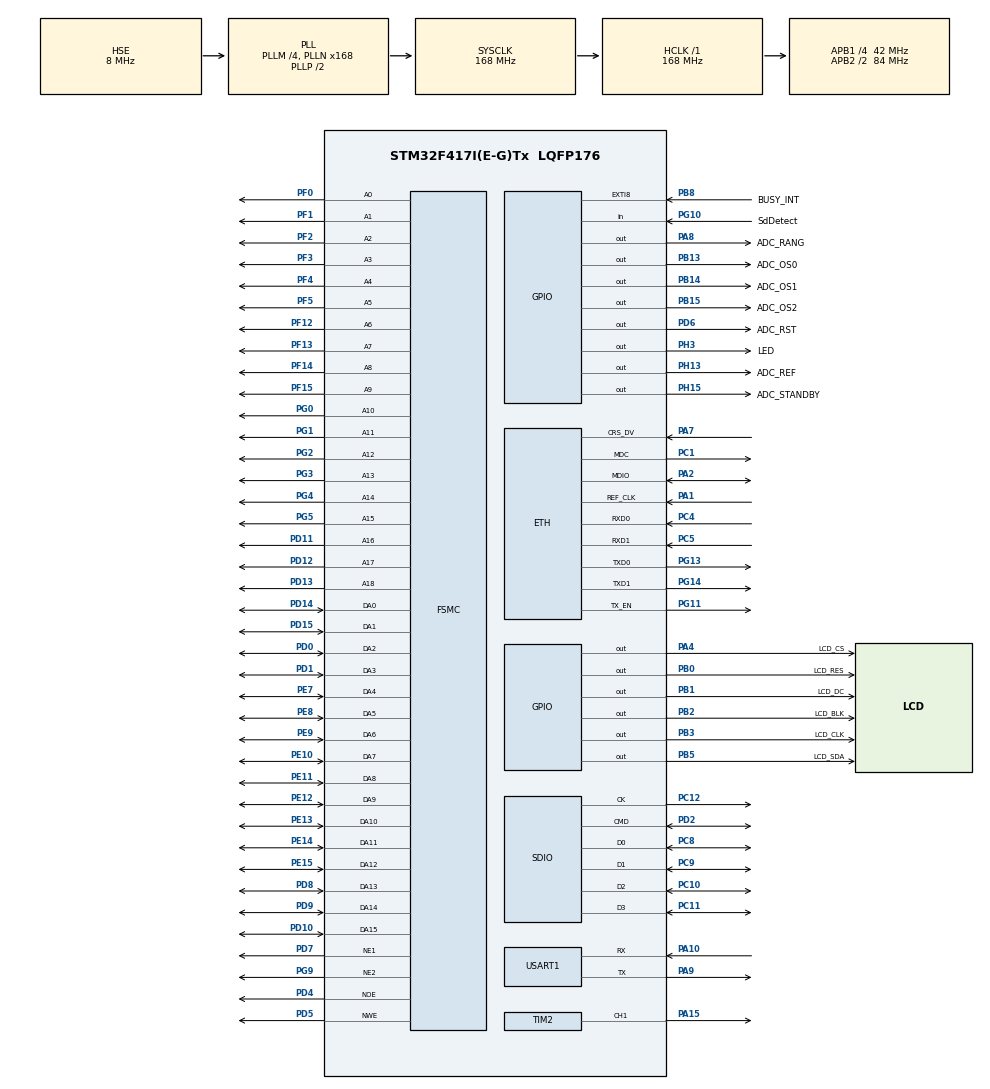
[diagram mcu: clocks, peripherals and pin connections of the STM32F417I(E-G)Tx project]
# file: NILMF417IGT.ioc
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Dma.MEMTOMEM.0.Direction=DMA_MEMORY_TO_MEMORY
Dma.MEMTOMEM.0.FIFOMode=DMA_FIFOMODE_ENABLE
Dma.MEMTOMEM.0.FIFOThreshold=DMA_FIFO_THRESHOLD_FULL
Dma.MEMTOMEM.0.Instance=DMA2_Stream0
Dma.MEMTOMEM.0.MemBurst=DMA_MBURST_SINGLE
Dma.MEMTOMEM.0.MemDataAlignment=DMA_MDATAALIGN_HALFWORD
Dma.MEMTOMEM.0.MemInc=DMA_MINC_ENABLE
Dma.MEMTOMEM.0.Mode=DMA_NORMAL
Dma.MEMTOMEM.0.PeriphBurst=DMA_PBURST_SINGLE
Dma.MEMTOMEM.0.PeriphDataAlignment=DMA_PDATAALIGN_HALFWORD
Dma.MEMTOMEM.0.PeriphInc=DMA_PINC_DISABLE
Dma.MEMTOMEM.0.Priority=DMA_PRIORITY_VERY_HIGH
Dma.Request0=MEMTOMEM
Dma.Request1=USART1_TX
Dma.Request2=SDIO_RX
Dma.Request3=SDIO_TX
Dma.SDIO_RX.2.Direction=DMA_PERIPH_TO_MEMORY
Dma.SDIO_RX.2.FIFOMode=DMA_FIFOMODE_ENABLE
Dma.SDIO_RX.2.FIFOThreshold=DMA_FIFO_THRESHOLD_FULL
Dma.SDIO_RX.2.Instance=DMA2_Stream3
Dma.SDIO_RX.2.MemBurst=DMA_MBURST_INC4
Dma.SDIO_RX.2.MemDataAlignment=DMA_MDATAALIGN_WORD
Dma.SDIO_RX.2.MemInc=DMA_MINC_ENABLE
Dma.SDIO_RX.2.Mode=DMA_PFCTRL
Dma.SDIO_RX.2.PeriphBurst=DMA_PBURST_INC4
Dma.SDIO_RX.2.PeriphDataAlignment=DMA_PDATAALIGN_WORD
Dma.SDIO_RX.2.PeriphInc=DMA_PINC_DISABLE
Dma.SDIO_RX.2.Priority=DMA_PRIORITY_VERY_HIGH
Dma.SDIO_TX.3.Direction=DMA_MEMORY_TO_PERIPH
Dma.SDIO_TX.3.FIFOMode=DMA_FIFOMODE_ENABLE
Dma.SDIO_TX.3.FIFOThreshold=DMA_FIFO_THRESHOLD_FULL
Dma.SDIO_TX.3.Instance=DMA2_Stream6
Dma.SDIO_TX.3.MemBurst=DMA_MBURST_INC4
Dma.SDIO_TX.3.MemDataAlignment=DMA_MDATAALIGN_WORD
Dma.SDIO_TX.3.MemInc=DMA_MINC_ENABLE
Dma.SDIO_TX.3.Mode=DMA_PFCTRL
Dma.SDIO_TX.3.PeriphBurst=DMA_PBURST_INC4
Dma.SDIO_TX.3.PeriphDataAlignment=DMA_PDATAALIGN_WORD
Dma.SDIO_TX.3.PeriphInc=DMA_PINC_DISABLE
Dma.SDIO_TX.3.Priority=DMA_PRIORITY_VERY_HIGH
Dma.USART1_TX.1.Direction=DMA_MEMORY_TO_PERIPH
Dma.USART1_TX.1.FIFOMode=DMA_FIFOMODE_ENABLE
Dma.USART1_TX.1.FIFOThreshold=DMA_FIFO_THRESHOLD_FULL
Dma.USART1_TX.1.Instance=DMA2_Stream7
Dma.USART1_TX.1.MemBurst=DMA_MBURST_SINGLE
Dma.USART1_TX.1.MemDataAlignment=DMA_MDATAALIGN_BYTE
Dma.USART1_TX.1.MemInc=DMA_MINC_ENABLE
Dma.USART1_TX.1.Mode=DMA_NORMAL
Dma.USART1_TX.1.PeriphBurst=DMA_PBURST_SINGLE
Dma.USART1_TX.1.PeriphDataAlignment=DMA_PDATAALIGN_BYTE
Dma.USART1_TX.1.PeriphInc=DMA_PINC_DISABLE
Dma.USART1_TX.1.Priority=DMA_PRIORITY_VERY_HIGH
ETH.MediaInterface=ETH_MEDIA_INTERFACE_RMII
ETH.PHY_DUPLEX_STATUS=0x0010
ETH.PHY_Name_RMII=userPHY
ETH.PHY_SPEED_STATUS=0x0004
ETH.PHY_SR=0x1F
ETH.PHY_User_Name=LAN8720A
ETH.PhyAddress=0
FSMC.AddressSetupTime2=15
FSMC.BusTurnAroundDuration2=15
FSMC.DataSetupTime2=255
FSMC.ExtendedMode2=FSMC_EXTENDED_MODE_DISABLE
FSMC.WriteOperation1=FSMC_WRITE_OPERATION_ENABLE
FSMC.WriteOperation2=FSMC_WRITE_OPERATION_ENABLE
LWIP.GATEWAY_ADDRESS=192.168.008.001
LWIP.IP_ADDRESS=192.168.008.156
LWIP.LWIP_DHCP=0
LWIP.MEMP_NUM_PBUF=50
LWIP.MEMP_NUM_TCP_SEG=128
LWIP.MEM_SIZE=30720
LWIP.NETMASK_ADDRESS=255.255.255.000
LWIP.PBUF_POOL_BUFSIZE=2067
LWIP.PBUF_POOL_SIZE=16
LWIP.TCP_MSS=1460
LWIP.TCP_SND_BUF=93440
LWIP.TCP_SND_QUEUELEN=128
LWIP.TCP_WND=5840
LWIP.Version=v2.1.2_Cube
Mcu.Family=STM32F4
Mcu.Name=STM32F417I(E-G)Tx
Mcu.Package=LQFP176
NVIC.DMA2_Stream0_IRQn=true\:0\:0\:false\:false\:true\:true\:true\:true
NVIC.DMA2_Stream3_IRQn=true\:0\:0\:false\:false\:true\:false\:true\:true
NVIC.DMA2_Stream6_IRQn=true\:0\:0\:false\:false\:true\:false\:true\:true
NVIC.DMA2_Stream7_IRQn=true\:0\:0\:false\:false\:true\:false\:true\:true
NVIC.ETH_IRQn=true\:0\:0\:false\:false\:true\:true\:true\:true
NVIC.EXTI9_5_IRQn=true\:0\:0\:true\:false\:true\:true\:true\:true
NVIC.FPU_IRQn=true\:0\:0\:false\:false\:true\:true\:false\:true
NVIC.PriorityGroup=NVIC_PRIORITYGROUP_4
NVIC.RCC_IRQn=true\:0\:0\:false\:false\:true\:true\:false\:true
NVIC.SDIO_IRQn=true\:0\:0\:false\:false\:true\:true\:true\:true
NVIC.TIM2_IRQn=true\:0\:0\:false\:false\:true\:true\:true\:true
NVIC.USART1_IRQn=true\:0\:0\:false\:false\:true\:true\:true\:true
PA1.Mode=RMII
PA1.Signal=ETH_REF_CLK
PA10.Mode=Asynchronous
PA10.Signal=USART1_RX
PA13.Mode=Serial_Wire
PA13.Signal=SYS_JTMS-SWDIO
PA14.Mode=Serial_Wire
PA14.Signal=SYS_JTCK-SWCLK
PA15.Signal=S_TIM2_CH1_ETR
PA2.Mode=RMII
PA2.Signal=ETH_MDIO
PA4.GPIO_Label=LCD_CS
PA4.GPIO_PuPd=GPIO_PULLUP
PA4.PinState=GPIO_PIN_SET
PA4.Signal=GPIO_Output
PA7.Mode=RMII
PA7.Signal=ETH_CRS_DV
PA8.GPIO_Label=ADC_RANG
PA8.Signal=GPIO_Output
PA9.Mode=Asynchronous
PA9.Signal=USART1_TX
PB0.GPIO_Label=LCD_RES
PB0.Signal=GPIO_Output
PB1.GPIO_Label=LCD_DC
PB1.Signal=GPIO_Output
PB13.GPIO_Label=ADC_OS0
PB13.Signal=GPIO_Output
PB14.GPIO_Label=ADC_OS1
PB14.Signal=GPIO_Output
PB15.GPIO_Label=ADC_OS2
PB15.Signal=GPIO_Output
PB2.GPIO_Label=LCD_BLK
PB2.Signal=GPIO_Output
PB3.GPIO_Label=LCD_CLK
PB3.Signal=GPIO_Output
PB5.GPIO_Label=LCD_SDA
PB5.Signal=GPIO_Output
PB8.GPIO_Label=BUSY_INT
PB8.Signal=GPXTI8
PC1.Mode=RMII
PC1.Signal=ETH_MDC
PC10.Mode=SD_4_bits_Wide_bus
PC10.Signal=SDIO_D2
PC11.Mode=SD_4_bits_Wide_bus
PC11.Signal=SDIO_D3
PC12.Mode=SD_4_bits_Wide_bus
PC12.Signal=SDIO_CK
PC14-OSC32_IN.Mode=LSE-External-Oscillator
PC14-OSC32_IN.Signal=RCC_OSC32_IN
PC15-OSC32_OUT.Mode=LSE-External-Oscillator
PC15-OSC32_OUT.Signal=RCC_OSC32_OUT
PC4.Mode=RMII
PC4.Signal=ETH_RXD0
PC5.Mode=RMII
PC5.Signal=ETH_RXD1
PC8.Mode=SD_4_bits_Wide_bus
PC8.Signal=SDIO_D0
PC9.Mode=SD_4_bits_Wide_bus
PC9.Signal=SDIO_D1
PD0.Signal=FSMC_D2_DA2
PD1.Signal=FSMC_D3_DA3
PD10.Signal=FSMC_D15_DA15
PD11.Signal=FSMC_A16_CLE
PD12.Signal=FSMC_A17_ALE
PD13.Signal=FSMC_A18
PD14.Signal=FSMC_D0_DA0
PD15.Signal=FSMC_D1_DA1
PD2.Mode=SD_4_bits_Wide_bus
PD2.Signal=SDIO_CMD
PD4.Signal=FSMC_NOE
PD5.Signal=FSMC_NWE
PD6.GPIO_Label=ADC_RST
PD6.Signal=GPIO_Output
PD7.Mode=NorPsramChipSelect1_1
PD7.Signal=FSMC_NE1
PD8.Signal=FSMC_D13_DA13
PD9.Signal=FSMC_D14_DA14
PE10.Signal=FSMC_D7_DA7
PE11.Signal=FSMC_D8_DA8
PE12.Signal=FSMC_D9_DA9
PE13.Signal=FSMC_D10_DA10
PE14.Signal=FSMC_D11_DA11
PE15.Signal=FSMC_D12_DA12
PE7.Signal=FSMC_D4_DA4
PE8.Signal=FSMC_D5_DA5
PE9.Signal=FSMC_D6_DA6
PF0.Signal=FSMC_A0
PF1.Signal=FSMC_A1
PF12.Signal=FSMC_A6
PF13.Signal=FSMC_A7
PF14.Signal=FSMC_A8
PF15.Signal=FSMC_A9
PF2.Signal=FSMC_A2
PF3.Signal=FSMC_A3
PF4.Signal=FSMC_A4
PF5.Signal=FSMC_A5
PG0.Signal=FSMC_A10
PG1.Signal=FSMC_A11
PG10.GPIO_Label=SdDetect
PG10.Signal=GPIO_Input
PG11.Mode=RMII
PG11.Signal=ETH_TX_EN
PG13.Mode=RMII
PG13.Signal=ETH_TXD0
PG14.Mode=RMII
PG14.Signal=ETH_TXD1
PG2.Signal=FSMC_A12
PG3.Signal=FSMC_A13
PG4.Signal=FSMC_A14
PG5.Signal=FSMC_A15
PG9.Mode=NorPsramChipSelect2_2
PG9.Signal=FSMC_NE2
PH0-OSC_IN.Mode=HSE-External-Oscillator
PH0-OSC_IN.Signal=RCC_OSC_IN
PH1-OSC_OUT.Mode=HSE-External-Oscillator
PH1-OSC_OUT.Signal=RCC_OSC_OUT
PH13.GPIO_Label=ADC_REF
PH13.Signal=GPIO_Output
PH15.GPIO_Label=ADC_STANDBY
PH15.Signal=GPIO_Output
PH3.GPIO_Label=LED
PH3.Signal=GPIO_Output
ProjectManager.HeapSize=0x1800
ProjectManager.StackSize=0x400
ProjectManager.TargetToolchain=Makefile
RCC.48MHZClocksFreq_Value=48000000
RCC.AHBFreq_Value=168000000
RCC.APB1CLKDivider=RCC_HCLK_DIV4
RCC.APB1Freq_Value=42000000
RCC.APB1TimFreq_Value=84000000
RCC.APB2CLKDivider=RCC_HCLK_DIV2
RCC.APB2Freq_Value=84000000
RCC.APB2TimFreq_Value=168000000
RCC.CortexFreq_Value=168000000
RCC.HCLKFreq_Value=168000000
RCC.HSE_VALUE=8000000
RCC.HSI_VALUE=16000000
RCC.PLLM=4
RCC.PLLN=168
RCC.PLLQ=7
RCC.PLLSourceVirtual=RCC_PLLSOURCE_HSE
RCC.RCC_RTC_Clock_Source=RCC_RTCCLKSOURCE_LSE
RCC.RCC_RTC_Clock_SourceVirtual=RCC_RTCCLKSOURCE_LSE
RCC.SYSCLKFreq_VALUE=168000000
RCC.SYSCLKSource=RCC_SYSCLKSOURCE_PLLCLK
RCC.VCOOutputFreq_Value=336000000
RTC.Date=6
RTC.Hours=20
RTC.Minutes=40
RTC.Month=RTC_MONTH_MARCH
RTC.Year=23
SDIO.ClockDiv=2
SH.FSMC_A0.0=FSMC_A0,19b-a2
SH.FSMC_A1.0=FSMC_A1,19b-a2
SH.FSMC_A10.0=FSMC_A10,19b-a2
SH.FSMC_A11.0=FSMC_A11,19b-a2
SH.FSMC_A12.0=FSMC_A12,19b-a2
SH.FSMC_A13.0=FSMC_A13,19b-a2
SH.FSMC_A14.0=FSMC_A14,19b-a2
SH.FSMC_A15.0=FSMC_A15,19b-a2
SH.FSMC_A16_CLE.0=FSMC_A16,19b-a2
SH.FSMC_A17_ALE.0=FSMC_A17,19b-a2
SH.FSMC_A18.0=FSMC_A18,19b-a2
SH.FSMC_A2.0=FSMC_A2,19b-a2
SH.FSMC_A3.0=FSMC_A3,19b-a2
SH.FSMC_A4.0=FSMC_A4,19b-a2
SH.FSMC_A5.0=FSMC_A5,19b-a2
SH.FSMC_A6.0=FSMC_A6,19b-a2
SH.FSMC_A7.0=FSMC_A7,19b-a2
SH.FSMC_A8.0=FSMC_A8,19b-a2
SH.FSMC_A9.0=FSMC_A9,19b-a2
SH.FSMC_D0_DA0.0=FSMC_DA0,16b-da1
SH.FSMC_D0_DA0.1=FSMC_D0,16b-d2
SH.FSMC_D10_DA10.0=FSMC_DA10,16b-da1
SH.FSMC_D10_DA10.1=FSMC_D10,16b-d2
SH.FSMC_D11_DA11.0=FSMC_DA11,16b-da1
SH.FSMC_D11_DA11.1=FSMC_D11,16b-d2
SH.FSMC_D12_DA12.0=FSMC_DA12,16b-da1
SH.FSMC_D12_DA12.1=FSMC_D12,16b-d2
SH.FSMC_D13_DA13.0=FSMC_DA13,16b-da1
SH.FSMC_D13_DA13.1=FSMC_D13,16b-d2
SH.FSMC_D14_DA14.0=FSMC_DA14,16b-da1
SH.FSMC_D14_DA14.1=FSMC_D14,16b-d2
SH.FSMC_D15_DA15.0=FSMC_DA15,16b-da1
SH.FSMC_D15_DA15.1=FSMC_D15,16b-d2
SH.FSMC_D1_DA1.0=FSMC_DA1,16b-da1
SH.FSMC_D1_DA1.1=FSMC_D1,16b-d2
SH.FSMC_D2_DA2.0=FSMC_DA2,16b-da1
SH.FSMC_D2_DA2.1=FSMC_D2,16b-d2
SH.FSMC_D3_DA3.0=FSMC_DA3,16b-da1
SH.FSMC_D3_DA3.1=FSMC_D3,16b-d2
SH.FSMC_D4_DA4.0=FSMC_DA4,16b-da1
SH.FSMC_D4_DA4.1=FSMC_D4,16b-d2
SH.FSMC_D5_DA5.0=FSMC_DA5,16b-da1
SH.FSMC_D5_DA5.1=FSMC_D5,16b-d2
SH.FSMC_D6_DA6.0=FSMC_DA6,16b-da1
SH.FSMC_D6_DA6.1=FSMC_D6,16b-d2
SH.FSMC_D7_DA7.0=FSMC_DA7,16b-da1
SH.FSMC_D7_DA7.1=FSMC_D7,16b-d2
SH.FSMC_D8_DA8.0=FSMC_DA8,16b-da1
SH.FSMC_D8_DA8.1=FSMC_D8,16b-d2
SH.FSMC_D9_DA9.0=FSMC_DA9,16b-da1
SH.FSMC_D9_DA9.1=FSMC_D9,16b-d2
SH.FSMC_NOE.0=FSMC_NOE,MuxedPsram1
SH.FSMC_NOE.1=FSMC_NOE,Sram2
SH.FSMC_NWE.0=FSMC_NWE,MuxedPsram1
SH.FSMC_NWE.1=FSMC_NWE,Sram2
SH.S_TIM2_CH1_ETR.0=TIM2_CH1,PWM Generation1 CH1
TIM2.AutoReloadPreload=TIM_AUTORELOAD_PRELOAD_ENABLE
TIM2.Channel-PWM\ Generation1\ CH1=TIM_CHANNEL_1
TIM2.Period=10-1
TIM2.Prescaler=164-1
TIM2.Pulse-PWM\ Generation1\ CH1=5-1
USART1.VirtualMode=VM_ASYNC
VP_CRC_VS_CRC.Mode=CRC_Activate
VP_LWIP_VS_Enabled.Mode=Enabled
VP_RTC_VS_RTC_Activate.Mode=RTC_Enabled
VP_RTC_VS_RTC_Calendar.Mode=RTC_Calendar
VP_TIM2_VS_ClockSourceINT.Mode=Internal
board=custom

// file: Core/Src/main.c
/* USER CODE BEGIN Header */
/**
 ******************************************************************************
 * @file           : main.c
 * @brief          : Main program body
 ******************************************************************************
 * @attention
 *
 * Copyright (c) 2023 STMicroelectronics.
 * All rights reserved.
 *
 * This software is licensed under terms that can be found in the LICENSE file
 * in the root directory of this software component.
 * If no LICENSE file comes with this software, it is provided AS-IS.
 *
 ******************************************************************************
 */
/* USER CODE END Header */
#include "main.h"
#include "crc.h"
#include "dma.h"
#include "lwip.h"
#include "rtc.h"
#include "sdio.h"
#include "tim.h"
#include "usart.h"
#include "gpio.h"
#include "fsmc.h"

/* USER CODE BEGIN Includes */
#include "ad7606.h"
#include "lcd_init.h"
#include "lcd.h"
#include "pic.h"

/* USER CODE END Includes */

/* USER CODE BEGIN PV */
AD7606Dev ad7606dev;
// AD7606Dev ad7606dev __attribute__((at(0X64080000)));
// struct netif gnetif;
// struct dhcp *dhcp;
/* USER CODE END PV */

void SystemClock_Config(void);

int main(void)
{

  /* MCU Configuration--------------------------------------------------------*/

  /* Reset of all peripherals, Initializes the Flash interface and the Systick. */
  HAL_Init();

  /* Configure the system clock */
  SystemClock_Config();

  /* Initialize all configured peripherals */
  MX_GPIO_Init();
  MX_DMA_Init();
  MX_TIM2_Init();
  MX_FSMC_Init();
  MX_SDIO_SD_Init();
  MX_USART1_UART_Init();
  MX_RTC_Init();
  MX_LWIP_Init();
  MX_CRC_Init();
  /* USER CODE BEGIN 2 */

  TCP_Client_Init();

  printf("\r\nUsart1 Test11111!\r\n");
  ad7606ini(&ad7606dev);

  HAL_GPIO_WritePin(ADC_RST_GPIO_Port, ADC_RST_Pin, GPIO_PIN_SET);

  HAL_Delay(500);
  HAL_GPIO_WritePin(ADC_RST_GPIO_Port, ADC_RST_Pin, GPIO_PIN_RESET);
  HAL_TIM_PWM_Start(&htim2, TIM_CHANNEL_1);

  // TestRAM();

  // uint8_t CRCTest[20];
  // uint32_t CrCValue[3] = {0, 0, 0};
  // uint8_t CRC_Index = 0;
  // uint32_t CrcRes;
  // uint8_t k = 0;
  // // ff0007e7030701212c010141
  // // ff0007e7030701212c010141
  // CRCTest[CRC_Index++] = 0xff;
  // CRCTest[CRC_Index++] = 0x00;
  // CRCTest[CRC_Index++] = 0x07;
  // CRCTest[CRC_Index++] = 0xe7;

  // CRCTest[CRC_Index++] = 0x03;
  // CRCTest[CRC_Index++] = 0x07;
  // CRCTest[CRC_Index++] = 0x01;
  // CRCTest[CRC_Index++] = 0x21;

  // CRCTest[CRC_Index++] = 0x2c;
  // CRCTest[CRC_Index++] = 0x01;
  // CRCTest[CRC_Index++] = 0x01;
  // CRCTest[CRC_Index++] = 0x41;

  // CRCTest[CRC_Index++] = 0xe7;
  // CRCTest[CRC_Index++] = 0x07;
  // CRCTest[CRC_Index++] = 0x00;
  // CRCTest[CRC_Index++] = 0xff;

  // CRCTest[CRC_Index++] = 0x21;
  // CRCTest[CRC_Index++] = 0x01;
  // CRCTest[CRC_Index++] = 0x07;
  // CRCTest[CRC_Index++] = 0x03;

  // CRCTest[CRC_Index++] = 0x41;
  // CRCTest[CRC_Index++] = 0x01;
  // CRCTest[CRC_Index++] = 0x01;
  // CRCTest[CRC_Index++] = 0x2c;

  // for (uint8_t i = 0; i < CRC_Index; i = i + 4)
  // {
  //   uint8_t t = i + 3;
  //   CrCValue[k] = CRCTest[t--];
  //   CrCValue[k] += CRCTest[t--] << 8;
  //   CrCValue[k] += CRCTest[t--] << 16;
  //   CrCValue[k] += CRCTest[t--] << 24;
  //   k++;
  // }

  // CrcRes = HAL_CRC_Calculate(&hcrc, (uint32_t *)CrCValue, 3);
  // CRCTest[CRC_Index++] = CrcRes;

  // LWIP_Send_data(CRCTest, CRC_Index, 1);

  /* USER CODE END 2 */

  /* Infinite loop */
  /* USER CODE BEGIN WHILE */
  while (1)
  {
    ana_AD7606();
    // lv_timer_handler();
    // HAL_Delay(5);
    MX_LWIP_Process();

    /* USER CODE END WHILE */

  }
}

void SystemClock_Config(void)
{
  RCC_OscInitTypeDef RCC_OscInitStruct = {0};
  RCC_ClkInitTypeDef RCC_ClkInitStruct = {0};

  /** Configure the main internal regulator output voltage
  */
  __HAL_RCC_PWR_CLK_ENABLE();
  __HAL_PWR_VOLTAGESCALING_CONFIG(PWR_REGULATOR_VOLTAGE_SCALE1);
  /** Initializes the RCC Oscillators according to the specified parameters
  * in the RCC_OscInitTypeDef structure.
  */
  RCC_OscInitStruct.OscillatorType = RCC_OSCILLATORTYPE_HSE|RCC_OSCILLATORTYPE_LSE;
  RCC_OscInitStruct.HSEState = RCC_HSE_ON;
  RCC_OscInitStruct.LSEState = RCC_LSE_ON;
  RCC_OscInitStruct.PLL.PLLState = RCC_PLL_ON;
  RCC_OscInitStruct.PLL.PLLSource = RCC_PLLSOURCE_HSE;
  RCC_OscInitStruct.PLL.PLLM = 4;
  RCC_OscInitStruct.PLL.PLLN = 168;
  RCC_OscInitStruct.PLL.PLLP = RCC_PLLP_DIV2;
  RCC_OscInitStruct.PLL.PLLQ = 7;
  if (HAL_RCC_OscConfig(&RCC_OscInitStruct) != HAL_OK)
  {
    Error_Handler();
  }
  /** Initializes the CPU, AHB and APB buses clocks
  */
  RCC_ClkInitStruct.ClockType = RCC_CLOCKTYPE_HCLK|RCC_CLOCKTYPE_SYSCLK
                              |RCC_CLOCKTYPE_PCLK1|RCC_CLOCKTYPE_PCLK2;
  RCC_ClkInitStruct.SYSCLKSource = RCC_SYSCLKSOURCE_PLLCLK;
  RCC_ClkInitStruct.AHBCLKDivider = RCC_SYSCLK_DIV1;
  RCC_ClkInitStruct.APB1CLKDivider = RCC_HCLK_DIV4;
  RCC_ClkInitStruct.APB2CLKDivider = RCC_HCLK_DIV2;

  if (HAL_RCC_ClockConfig(&RCC_ClkInitStruct, FLASH_LATENCY_5) != HAL_OK)
  {
    Error_Handler();
  }
}

void Error_Handler(void)
{
  __disable_irq();
  while (1)
  {
  }
}
